# GD32W515Px register map
File version: 1.0
CPU: CM33 r0p0, little endian, MPU, FPU, 4 interrupt priority bits
Registers are 32-bit, read-write, reset 0x0 unless marked. A register's access mark holds for its fields unless they carry their own. Offsets are from the block's base; [hi:lo] are bit positions; {n}, {i} and the like mark numbered series.

## PKCAU — Public Key Cryptographic Acceleration Unit
Base 0x4C061000
Same registers: SEC_PKCAU 0x5C061000
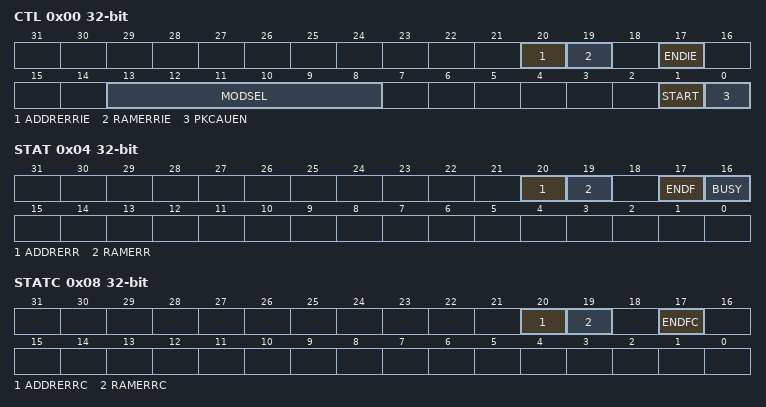
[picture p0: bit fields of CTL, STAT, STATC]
0x00 CTL — Control register
  [20] ADDRERRIE — Address error interrupt enable
  [19] RAMERRIE — RAM error interrupt enable
  [17] ENDIE — End of operation interrupt enable
  [13:8] MODSEL — PKCAU operation mode selection
  [1] START — PKCAU starts operation
  [0] PKCAUEN — PKCAU enable
0x04 STAT ro — Status register
  [20] ADDRERR — Address error
  [19] RAMERR — PKCAU RAM error
  [17] ENDF — End of PKCAU operation
  [16] BUSY — Busy flag
0x08 STATC wo — Status clear register
  [20] ADDRERRC — Address error flag clear
  [19] RAMERRC — PKCAU RAM error flag clear
  [17] ENDFC — End of PKCAU operation flag clear

## HAU — HAU acceleration unit
Base 0x4C060400
Same registers: SEC_HAU 0x5C060400
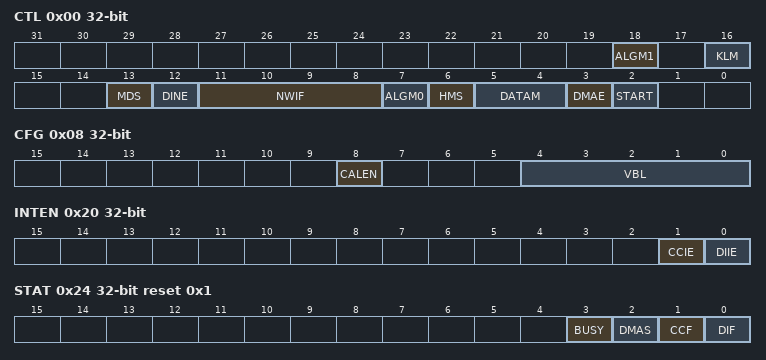
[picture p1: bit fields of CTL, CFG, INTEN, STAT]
0x00 CTL access per field — HAU control register
  [18] ALGM1 rw — Algorithm selection bit 1
  [16] KLM rw — Key length mode
  [13] MDS rw — Multiple DMA selection
  [12] DINE ro — DI register is not empty
  [11:8] NWIF ro — Number of words in IN FIFO
  [7] ALGM0 rw — Algorithm selection bit 0
  [6] HMS rw — HAU mode selection
  [5:4] DATAM rw — Data type mode
  [3] DMAE rw — DMA enable
  [2] START wo — Start message digest calculation
0x04 DI — HAU data input register
  [31:0] DI — Message data input
0x08 CFG access per field — HAU configuration register
  [8] CALEN wo — Digest calculation enable
  [4:0] VBL rw — Valid bits length in the last word
{0xC+4i} DO{i} ro (i=0..4) — HAU data output register
  [31:0] DO{i} — message digest result of hash algorithm
0x20 INTEN — HAU interrupt enable register
  [1] CCIE — calculation completion interrupt enable
  [0] DIIE — Data input interrupt enable
0x24 STAT ro reset 0x1 — HAU status and interrupt flag register
  [3] BUSY — Busy flag bit
  [2] DMAS — DMA status flag
  [1] CCF — Digest calculation completion flag
  [0] DIF — Data input flag
0xF8 CTXS0 reset 0x2 — Context switch register x
  [31:0] CTX0 — The complete internal status
{0xF8+4i} CTXS{i} (i=1..53) — Context switch register x
  [31:0] CTX{i} — The complete internal status
{0x310+4i} DO{i} ro (i=5..7) — HAU data output register
  [31:0] DO{i} — message digest result of hash algorithm

## TIMER16 — General-purpose-timers
Base 0x40018400
Same registers: TIMER15 0x40018000, SEC_TIMER15 0x50018000, SEC_TIMER16 0x50018400
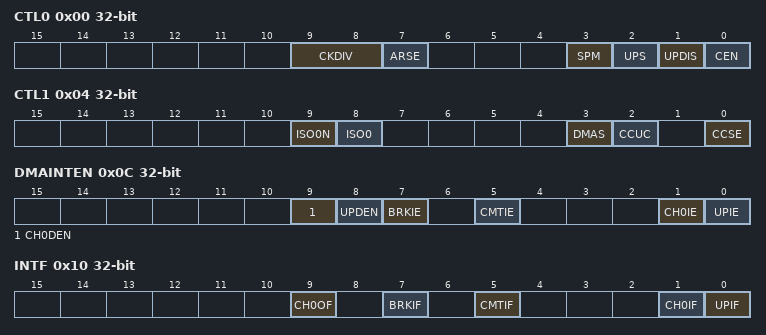
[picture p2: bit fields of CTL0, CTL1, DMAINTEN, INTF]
0x00 CTL0 — control register 0
  [9:8] CKDIV — Clock division
  [7] ARSE — Auto-reload preload enable
  [3] SPM — One-pulse mode
  [2] UPS — Update request source
  [1] UPDIS — Update disable
  [0] CEN — Counter enable
0x04 CTL1 — control register 1
  [9] ISO0N — Output Idle state 0
  [8] ISO0 — Output Idle state 0
  [3] DMAS — Capture/compare DMA selection
  [2] CCUC — Capture/compare control update selection
  [0] CCSE — Capture/compare preloaded control
0x0C DMAINTEN — DMA/Interrupt enable register
  [9] CH0DEN — Capture/Compare 0 DMA request enable
  [8] UPDEN — Update DMA request enable
  [7] BRKIE — Break interrupt enable
  [5] CMTIE — COM interrupt enable
  [1] CH0IE — Capture/Compare 0 interrupt enable
  [0] UPIE — Update interrupt enable
0x10 INTF — interrupt flag register
  [9] CH0OF — Capture/Compare 0 overcapture flag
  [7] BRKIF — Break interrupt flag
  [5] CMTIF — COM interrupt flag
  [1] CH0IF — Capture/compare 0 interrupt flag
  [0] UPIF — Update interrupt flag
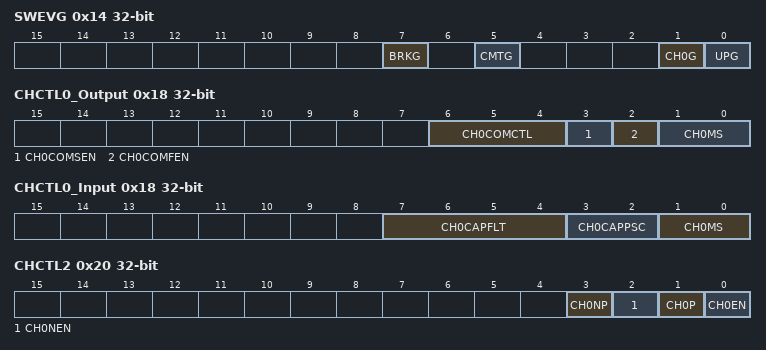
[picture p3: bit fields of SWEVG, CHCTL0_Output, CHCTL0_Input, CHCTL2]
0x14 SWEVG wo — event generation register
  [7] BRKG — Break generation
  [5] CMTG — Capture/Compare control update generation
  [1] CH0G — Capture/compare 0 generation
  [0] UPG — Update generation
0x18 CHCTL0_Output — capture/compare mode register (output mode)
  [6:4] CH0COMCTL — Output Compare 0 mode
  [3] CH0COMSEN — Output Compare 0 preload enable
  [2] CH0COMFEN — Output Compare 0 fast enable
  [1:0] CH0MS — Capture/Compare 0 selection
0x18 CHCTL0_Input (alternate view of CHCTL0_Output) — capture/compare mode register 0 (input mode)
  [7:4] CH0CAPFLT — Input capture 0 filter
  [3:2] CH0CAPPSC — Input capture 0 prescaler
  [1:0] CH0MS — Capture/Compare 0 selection
0x20 CHCTL2 — capture/compare enable register
  [3] CH0NP — Capture/Compare 0 output Polarity
  [2] CH0NEN — Capture/Compare 0 complementary output enable
  [1] CH0P — Capture/Compare 0 output Polarity
  [0] CH0EN — Capture/Compare 0 output enable
0x24 CNT — counter
  [15:0] CNT — counter value
0x28 PSC — prescaler
  [15:0] PSC — Prescaler value
0x2C CAR — auto-reload register
  [15:0] CARL — Auto-reload value
0x30 CREP — repetition counter register
  [7:0] CREP — Repetition counter value
0x34 CH0CV — capture/compare register 0
  [15:0] CH0VAL — Capture/Compare 0 value
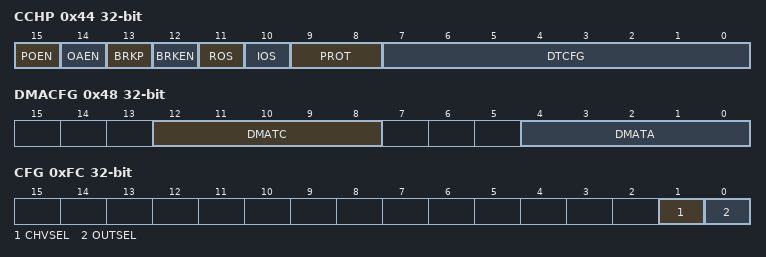
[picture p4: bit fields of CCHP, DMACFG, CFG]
0x44 CCHP — break and dead-time register
  [15] POEN — Main output enable
  [14] OAEN — Automatic output enable
  [13] BRKP — Break polarity
  [12] BRKEN — Break enable
  [11] ROS — Off-state selection for Run mode
  [10] IOS — Off-state selection for Idle mode
  [9:8] PROT — complementary register protect control
  [7:0] DTCFG — Dead-time generator setup
0x48 DMACFG — DMA configuration register
  [12:8] DMATC — DMA transfer count
  [4:0] DMATA — DMA transfer access start address
0x4C DMATB — DMA transfer buffer register
  [15:0] DMATB — DMA register for burst accesses
0xFC CFG — configuration register
  [1] CHVSEL — Write CHxVAL register selection
  [0] OUTSEL — The output value selection
